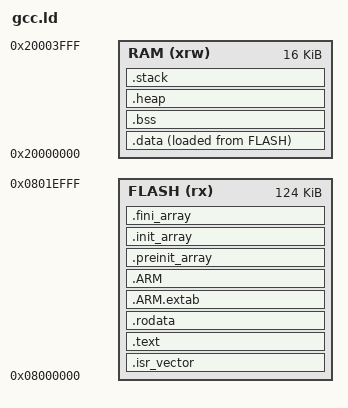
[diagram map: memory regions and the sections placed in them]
/*
*****************************************************************************
*/

ENTRY(Reset_Handler)

_estack = 0x20004000;

_HEAP_SIZE = 0x0000;
_STACK_SIZE = 0x1000;

MEMORY
{
    FLASH (rx)      :  ORIGIN = 0x08000000, LENGTH = 124K
    RAM (xrw)       :  ORIGIN = 0x20000000, LENGTH = 16K
}

SECTIONS
{
  .isr_vector :
  {
    . = ALIGN(4);
    KEEP(*(.isr_vector))
    . = ALIGN(4);
  } >FLASH

  .text :
  {
    . = ALIGN(4);
    *(.text)
    *(.text*)
    *(.glue_7)
    *(.glue_7t)
    *(.eh_frame)

    KEEP (*(.init))
    KEEP (*(.fini))

    . = ALIGN(4);
    _etext = .;
  } >FLASH

  .rodata :
  {
    . = ALIGN(4);
    *(.rodata)
    *(.rodata*)
    . = ALIGN(4);
  } >FLASH

  .ARM.extab   : { *(.ARM.extab* .gnu.linkonce.armextab.*) } >FLASH
  .ARM : {
    __exidx_start = .;
    *(.ARM.exidx*)
    __exidx_end = .;
  } >FLASH

  .preinit_array     :
  {
    PROVIDE_HIDDEN (__preinit_array_start = .);
    KEEP (*(.preinit_array*))
    PROVIDE_HIDDEN (__preinit_array_end = .);
  } >FLASH

  .init_array :
  {
    PROVIDE_HIDDEN (__init_array_start = .);
    KEEP (*(SORT(.init_array.*)))
    KEEP (*(.init_array*))
    PROVIDE_HIDDEN (__init_array_end = .);
  } >FLASH

  .fini_array :
  {
    PROVIDE_HIDDEN (__fini_array_start = .);
    KEEP (*(SORT(.fini_array.*)))
    KEEP (*(.fini_array*))
    PROVIDE_HIDDEN (__fini_array_end = .);
  } >FLASH

  _sidata = LOADADDR(.data);

  .data :
  {
    . = ALIGN(4);
    _sdata = .;
    *(.data)
    *(.data*)

    . = ALIGN(4);
    _edata = .;
  } >RAM  AT>FLASH

  . = ALIGN(4);
  .bss :
  {
    _sbss = .;
    __bss_start__ = _sbss;
    *(.bss)
    *(.bss*)
    *(COMMON)

    . = ALIGN(4);
    _ebss = .;
    __bss_end__ = _ebss;
  } >RAM

  .heap :
  {
     . = ALIGN(4);
     _heap_bottom = . ;
     end = _heap_bottom;
     _end = end;
     __end = end;
     . += _HEAP_SIZE ;
     _heap_top = .;
  } >RAM

  .stack :
  {
     . = ALIGN(4);
     _stack_bottom = . ;
     . += _STACK_SIZE ;
     _stack_top = .;
  } >RAM

  /DISCARD/ :
  {
    libc.a ( * )
    libm.a ( * )
    libgcc.a ( * )
  }

  .ARM.attributes 0 : { *(.ARM.attributes) }
}
